# K1921VG7T register map
Vendor: NIIET; Series: K1921VKx; File version: 1.0
CPU: CM4 r0p1, Endian.LITTLE endian, MPU, FPU
Registers are 32-bit, read-write, reset 0x0 unless marked. A register's access mark holds for its fields unless they carry their own. Offsets are from the block's base; [hi:lo] are bit positions; lines under a group give offsets from that group; {n}, {i} and the like mark numbered series; 'fields as' and 'values as' point back to an identical list.

## SIU — System interconnect unit
Base 0x50003000
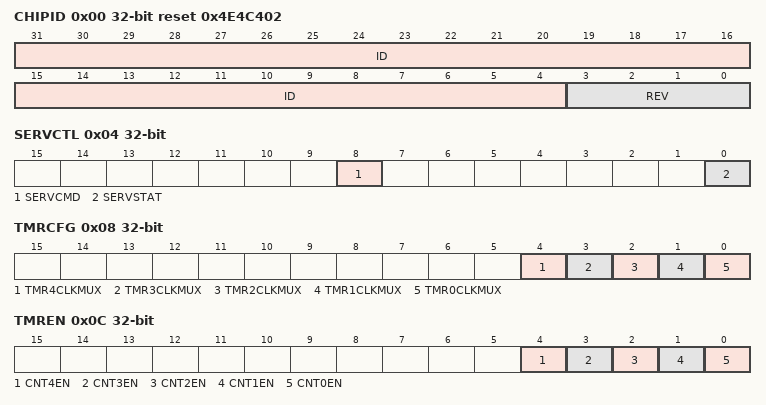
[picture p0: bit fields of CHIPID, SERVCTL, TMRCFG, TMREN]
0x00 CHIPID ro reset 0x4E4C402 — Chip identifier
  [31:4] ID — Model ID
  [3:0] REV — Revision number
0x04 SERVCTL — Service mode Register
  [8] SERVCMD — Service mode erase comand/status
  [0] SERVSTAT ro — Service mode status
0x08 TMRCFG — Timers external clock config
  [all] fields
    0=EXTPIN (external controler pin); 1=PRETIMER (previous timer PWM-output)
  [4] TMR4CLKMUX — Select external clock source TMR16_2
  [3] TMR3CLKMUX — Select external clock source TMR16_1
  [2] TMR2CLKMUX — Select external clock source TMR16_1
  [1] TMR1CLKMUX — Select external clock source TMR32_1
  [0] TMR0CLKMUX — Select external clock source TMR32_0
0x0C TMREN — Timers counting enable register
  [4] CNT4EN — TMR16_2 counting enable
  [3] CNT3EN — TMR16_1 counting enable
  [2] CNT2EN — TMR16_0 counting enable
  [1] CNT1EN — TMR32_1 counting enable
  [0] CNT0EN — TMR32_0 counting enable
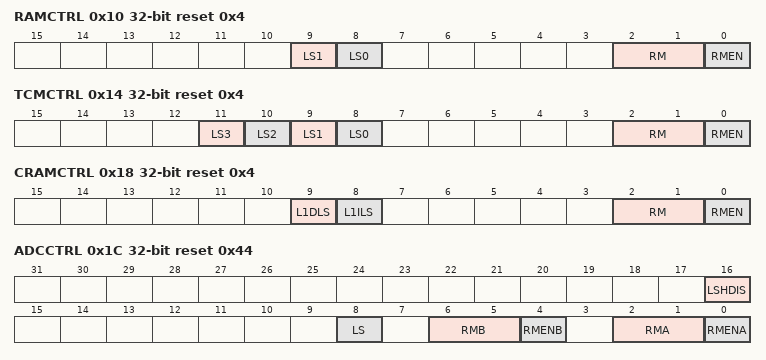
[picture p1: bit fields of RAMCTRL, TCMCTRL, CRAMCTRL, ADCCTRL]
0x10 RAMCTRL reset 0x4 — SRAM control register
  [9] LS1 — Ligth Sleep RAM part 1 (16k..32k)
  [8] LS0 — Ligth Sleep RAM part 0 (0..16k)
  [2:1] RM — Read-Write Margin value
  [0] RMEN — Enable to use Read-Write Margin
0x14 TCMCTRL reset 0x4 — Core Tightly-Coupled Memory SRAM control
  [11] LS3 — Ligth Sleep TCM RAM part 3 (24k..32k)
  [10] LS2 — Ligth Sleep TCM RAM part 2 (16..24k)
  [9] LS1 — Ligth Sleep TCM RAM part 1 (8k..16k)
  [8] LS0 — Ligth Sleep TCM RAM part 0 (0..8k)
  [2:1] RM — Read-Write Margin value
  [0] RMEN — Enable to use Read-Write Margin
0x18 CRAMCTRL reset 0x4 — Core Cache SRAM control
  [9] L1DLS — Ligth Sleep L1 Data cache RAM
  [8] L1ILS — Ligth Sleep L1 Instruction cache RAM
  [2:1] RM — Read-Write Margin value
  [0] RMEN — Enable to use Read-Write Margin
0x1C ADCCTRL reset 0x44 — ADC level shifters and DP SRAM control
  [16] LSHDIS — Disable Level-Shifters of ADC
  [8] LS — Ligth Sleep ADC Dual Port RAM
  [6:5] RMB — Read-Write Margin value (Port B)
  [4] RMENB — Enable to use Read-Write Margin (Port B)
  [2:1] RMA — Read-Write Margin value (Port A)
  [0] RMENA — Enable to use Read-Write Margin (Port A)
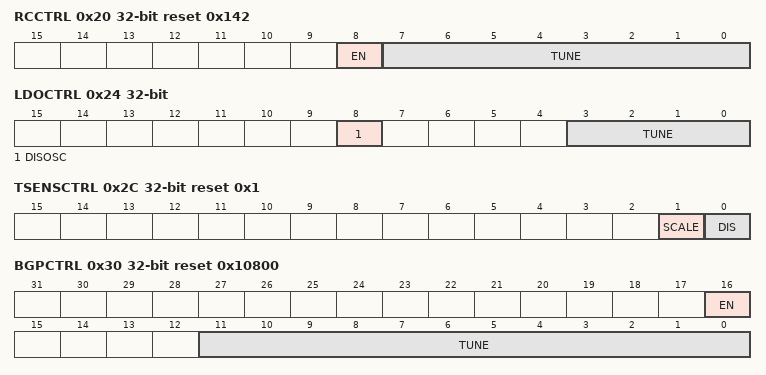
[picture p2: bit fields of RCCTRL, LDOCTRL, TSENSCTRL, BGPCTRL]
0x20 RCCTRL reset 0x142 — RC generator control register
  [8] EN — Internal oscillator enable
  [7:0] TUNE — Tune RC generator period
0x24 LDOCTRL — LDO control register
  [8] DISOSC — Disable oscillator 100kHz
  [3:0] TUNE — Tune LDO output voltage
0x2C TSENSCTRL reset 0x1 — Temperature sensor control register
  [1] SCALE — Scale out control
    0=OnePNJunction (Output voltage 1.14..1.75 (125..-40 C)); 1=TwoPNJunctions (Output voltage 0.575..0.88 (125..-40 C) - best choice)
  [0] DIS — Disable temperature sensor
0x30 BGPCTRL reset 0x10800 — Bandgap control register
  [16] EN — Enable bandgap
  [11:0] TUNE — Tune bandgap voltage
0x34 BOOTSELSTAT ro — BOOTSEL status register
  [0] BOOTSEL — BOOTSEL status
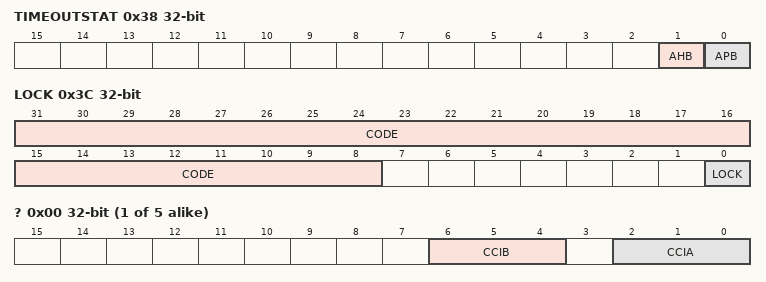
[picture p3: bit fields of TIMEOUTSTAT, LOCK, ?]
0x38 TIMEOUTSTAT ro — Timeouts statust register
  [1] AHB, [0] APB
0x3C LOCK — Lock configuration register
  [31:8] CODE wo — Write key 0xACCE55 to change LOCK bit value
    0xACCE55=CHANGE (Value that allows the LOCK bit to be changed); 0=DUMMY_0 (Example value that prevents the LOCK bit change); 1=DUMMY_1 (Example value that prevents the LOCK bit change)
  [0] LOCK — Write with specific code to lock / unlock writing to other SIU registers
0x40 APBTIMEOUT reset 0xFFF
  [11:0] VAL
0x44 AHBTIMEOUT reset 0xFFF
  [11:0] VAL
{0x60+4i} TMRMUX[{i}] (i=0..4) group
  0x00 ? — TMRn capture/compare inputs select
    [6:4] CCIB — Select signal for TMRxx CCIB input
      0=TMRIO_N (External pin tmr_io[n]); 1=TMRIO_N_P1 (External pin tmr_io[(n+1)%5]); 2=TMRIO_N_P2 (External pin tmr_io[(n+2)%5]); 3=TMRIO_N_P3 (External pin tmr_io[(n+3)%5]); 4=TMRIO_N_P4 (External pin tmr_io[(n+4)%5]); 5=GPIOA (GPIOA adc soc impulse); 6=GPIOB (GPIOB adc soc impulse)
    [2:0] CCIA — Select signal for TMRxx CCIA input
      values as CCIB
